VERSION ""

NS_ :

BS_:

BU_:

BO_ 3221225472 VECTOR__INDEPENDENT_SIG_MSG: 0 Vector__XXX
 SG_ Max_Cell_Temp : 56|8@1+ (1,-40) [-40|215] "C" Vector__XXX
 SG_ NewSignal_0004 : 24|8@1+ (1,0) [0|0] "" Vector__XXX
 SG_ TEMP_0 : 0|8@1+ (1,-40) [-40|215] "" Vector__XXX
 SG_ TEMP_1 : 8|8@1+ (1,-40) [-40|215] "" Vector__XXX
 SG_ TEMP_2 : 16|8@1+ (1,-40) [-40|215] "" Vector__XXX
 SG_ TEMP_3 : 24|8@1+ (1,-40) [-40|215] "" Vector__XXX
 SG_ TEMP_4 : 32|8@1+ (1,-40) [-40|215] "" Vector__XXX
 SG_ TEMP_5 : 40|8@1+ (1,-40) [-40|215] "" Vector__XXX
 SG_ TEMP_6 : 48|8@1+ (1,-40) [-40|215] "" Vector__XXX
 SG_ TEMP_0 : 0|8@1+ (1,-40) [-40|215] "" Vector__XXX
 SG_ TEMP_1 : 8|8@1+ (1,-40) [-40|215] "" Vector__XXX
 SG_ TEMP_2 : 16|8@1+ (1,-40) [-40|215] "" Vector__XXX
 SG_ TEMP_3 : 24|8@1+ (1,-40) [-40|215] "" Vector__XXX
 SG_ TEMP_4 : 32|8@1+ (1,-40) [-40|215] "" Vector__XXX
 SG_ TEMP_5 : 40|8@1+ (1,-40) [-40|215] "" Vector__XXX
 SG_ TEMP_6 : 48|8@1+ (1,-40) [-40|215] "" Vector__XXX
 SG_ TEMP_0 : 0|8@1+ (1,-40) [-40|215] "" Vector__XXX
 SG_ TEMP_1 : 8|8@1+ (1,-40) [-40|215] "" Vector__XXX
 SG_ TEMP_2 : 16|8@1+ (1,-40) [-40|215] "" Vector__XXX
 SG_ TEMP_3 : 24|8@1+ (1,-40) [-40|215] "" Vector__XXX
 SG_ TEMP_4 : 32|8@1+ (1,-40) [-40|215] "" Vector__XXX
 SG_ TEMP_5 : 40|8@1+ (1,-40) [-40|215] "" Vector__XXX
 SG_ TEMP_6 : 48|8@1+ (1,-40) [-40|215] "" Vector__XXX

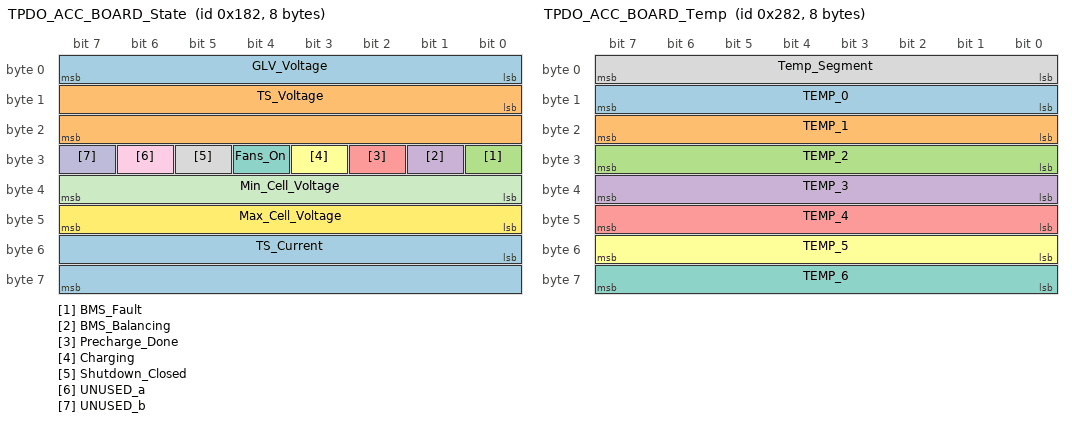
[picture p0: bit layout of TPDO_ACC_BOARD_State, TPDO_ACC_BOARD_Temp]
BO_ 386 TPDO_ACC_BOARD_State: 8 Vector__XXX
 SG_ GLV_Voltage : 0|8@1+ (0.1,0) [0|25.5] "Volts" Vector__XXX
 SG_ TS_Voltage : 8|16@1+ (0.1,0) [0|6553.5] "Volts" Vector__XXX
 SG_ BMS_Fault : 24|1@1+ (1,0) [0|0] "" Vector__XXX
 SG_ BMS_Balancing : 25|1@1+ (1,0) [0|0] "" Vector__XXX
 SG_ Precharge_Done : 26|1@1+ (1,0) [0|0] "" Vector__XXX
 SG_ Charging : 27|1@1+ (1,0) [0|0] "" Vector__XXX
 SG_ Fans_On : 28|1@1+ (1,0) [0|0] "" Vector__XXX
 SG_ Shutdown_Closed : 29|1@1+ (1,0) [0|0] "" Vector__XXX
 SG_ UNUSED_a : 30|1@1+ (1,0) [0|0] "" Vector__XXX
 SG_ UNUSED_b : 31|1@1+ (1,0) [0|0] "" Vector__XXX
 SG_ Min_Cell_Voltage : 32|8@1+ (0.02,0) [0|5.1] "Volts" Vector__XXX
 SG_ Max_Cell_Voltage : 40|8@1+ (0.02,0) [0|5.1] "Volts" Vector__XXX
 SG_ TS_Current : 48|16@1- (0.1,0) [-3276.8|3276.7] "Amps" Vector__XXX

BO_ 642 TPDO_ACC_BOARD_Temp: 8 Vector__XXX
 SG_ TEMP_0 : 8|8@1+ (1,-40) [-40|215] "" Vector__XXX
 SG_ TEMP_1 : 16|8@1+ (1,-40) [-40|215] "" Vector__XXX
 SG_ TEMP_2 : 24|8@1+ (1,-40) [-40|215] "" Vector__XXX
 SG_ TEMP_3 : 32|8@1+ (1,-40) [-40|215] "" Vector__XXX
 SG_ TEMP_4 : 40|8@1+ (1,-40) [-40|215] "" Vector__XXX
 SG_ TEMP_5 : 48|8@1+ (1,-40) [-40|215] "" Vector__XXX
 SG_ TEMP_6 : 56|8@1+ (1,-40) [-40|215] "" Vector__XXX
 SG_ Temp_Segment : 0|8@1+ (1,0) [0|255] "" Vector__XXX

BO_ 1794 NMT_ACC_HEARTBEAT: 8 Vector__XXX
 SG_ Status : 0|8@1+ (1,0) [0|255] "" Vector__XXX

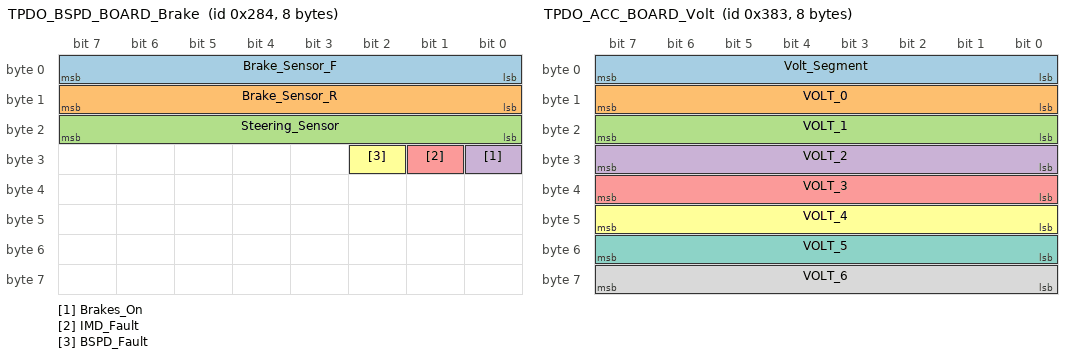
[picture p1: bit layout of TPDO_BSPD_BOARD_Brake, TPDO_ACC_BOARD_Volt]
BO_ 644 TPDO_BSPD_BOARD_Brake: 8 Vector__XXX
 SG_ Brake_Sensor_F : 0|8@1+ (0.5,0) [0|127.5] "percent" Vector__XXX
 SG_ Brake_Sensor_R : 8|8@1+ (0.5,0) [0|127.5] "percent" Vector__XXX
 SG_ Steering_Sensor : 16|8@1+ (1,-90) [-90|165] "degrees" Vector__XXX
 SG_ Brakes_On : 24|1@1+ (1,0) [0|1] "" Vector__XXX
 SG_ IMD_Fault : 25|1@1+ (1,0) [0|1] "" Vector__XXX
 SG_ BSPD_Fault : 26|1@1+ (1,0) [0|1] "" Vector__XXX

BO_ 899 TPDO_ACC_BOARD_Volt: 8 Vector__XXX
 SG_ Volt_Segment : 0|8@1+ (1,0) [0|0] "" Vector__XXX
 SG_ VOLT_0 : 8|8@1+ (0.02,0) [0|5.1] "V" Vector__XXX
 SG_ VOLT_1 : 16|8@1+ (0.02,0) [0|5.1] "V" Vector__XXX
 SG_ VOLT_2 : 24|8@1+ (0.02,0) [0|5.1] "V" Vector__XXX
 SG_ VOLT_3 : 32|8@1+ (0.02,0) [0|5.1] "V" Vector__XXX
 SG_ VOLT_4 : 40|8@1+ (0.02,0) [0|5.1] "V" Vector__XXX
 SG_ VOLT_5 : 48|8@1+ (0.02,0) [0|5.1] "V" Vector__XXX
 SG_ VOLT_6 : 56|8@1+ (0.02,0) [0|5.1] "V" Vector__XXX

CM_ SG_ 386 BMS_Fault "Fault High";
CM_ SG_ 386 BMS_Balancing "Balancing High";
CM_ SG_ 386 Precharge_Done "Done High";
CM_ SG_ 386 Charging "Charging High";
CM_ SG_ 386 Fans_On "On High";
CM_ SG_ 386 Shutdown_Closed "Closed High";
CM_ SG_ 644 Steering_Sensor "90 (left) to -90 (right)";
BA_DEF_ BO_  "CANFD_BRS" ENUM  "0","1";
BA_DEF_  "BusType" STRING ;
BA_DEF_ BO_  "VFrameFormat" ENUM  "StandardCAN","ExtendedCAN","StandardCAN_FD","ExtendedCAN_FD";
BA_DEF_DEF_  "CANFD_BRS" "1";
BA_DEF_DEF_  "BusType" "";
BA_DEF_DEF_  "VFrameFormat" "StandardCAN";
BA_ "BusType" "CAN FD";
VAL_ 642 Temp_Segment 1 "Segment 0" 2 "Segment 1" 3 "Segment 2" 4 "Segment 3" ;
VAL_ 1794 Status 0 "Boot up" 4 "Stopped" 5 "Operational" 127 "Pre-operational" ;
